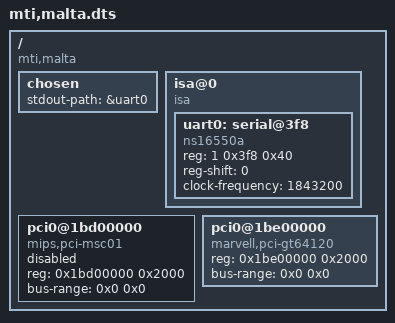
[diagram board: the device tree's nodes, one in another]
/dts-v1/;

/memreserve/ 0x00000000 0x00001000;	/* Exception vectors */
/memreserve/ 0x000f0000 0x00010000;	/* PIIX4 ISA memory */

/ {
	#address-cells = <1>;
	#size-cells = <1>;
	compatible = "mti,malta";

	chosen {
		stdout-path = &uart0;
	};

	isa@0 {
		compatible = "isa";
		#address-cells = <2>;
		#size-cells = <1>;
		ranges = <1 0 0 0x1000>;

		uart0: serial@3f8 {
			compatible = "ns16550a";

			reg = <1 0x3f8 0x40>;
			reg-shift = <0>;

			clock-frequency = <1843200>;

			bootph-all;
		};
	};

	pci0@1bd00000 {
		compatible = "mips,pci-msc01";
		device_type = "pci";
		reg = <0x1bd00000 0x2000>;

		#address-cells = <3>;
		#size-cells = <2>;
		bus-range = <0x0 0x0>;
		ranges = <0x01000000 0 0x00000000 0x00000000 0 0x800000		/* I/O */
			  0x02000000 0 0x10000000 0xb0000000 0 0x10000000	/* MEM */>;

		status = "disabled";
	};

	pci0@1be00000 {
		compatible = "marvell,pci-gt64120";
		device_type = "pci";
		reg = <0x1be00000 0x2000>;

		#address-cells = <3>;
		#size-cells = <2>;
		bus-range = <0x0 0x0>;
		ranges = <0x01000000 0 0x00000000 0x00000000 0 0x20000		/* I/O */
			  0x02000000 0 0x10000000 0x10000000 0 0x8000000	/* MEM */>;

		status = "okay";
	};
};
